VERSION ""

NS_ :

BS_:

BU_: DisplayVCAN

BO_ 3221225472 VECTOR__INDEPENDENT_SIG_MSG: 0 Vector__XXX
 SG_ motpump_min_pwm : 0|7@1+ (1,0) [0|127] "" Vector__XXX
 SG_ override_hvb_min_rpm_Copy_1 : 0|12@1+ (1,0) [0|4095] "RPM" Vector__XXX
 SG_ inv_sig_slope : 0|8@1+ (0.01,0) [0|2.55] "" Vector__XXX
 SG_ ice_fan_override : 0|1@1+ (1,0) [0|1] "" Vector__XXX
 SG_ ip_brk_Ldisp : 0|12@1+ (0.01,0) [0|40.95] "" Vector__XXX
 SG_ ip_brk_Rdisp : 0|12@1+ (0.01,0) [0|40.95] "" Vector__XXX
 SG_ ip_brk_pbrk_LED : 0|1@1+ (1,0) [0|1] "" Vector__XXX
 SG_ ip_brk_sbrk_R_end : 0|1@1+ (1,0) [0|1] "" Vector__XXX
 SG_ ip_brk_sbrk_L_end : 0|1@1+ (1,0) [0|1] "" Vector__XXX
 SG_ ip_brk_Lpres : 0|14@1+ (0.01,0) [0|163.83] "bar" Vector__XXX
 SG_ ip_brk_Rpres : 0|14@1+ (0.01,0) [0|163.83] "bar" Vector__XXX
 SG_ Mushroom_Button : 0|1@1+ (1,0) [0|1] "" Vector__XXX

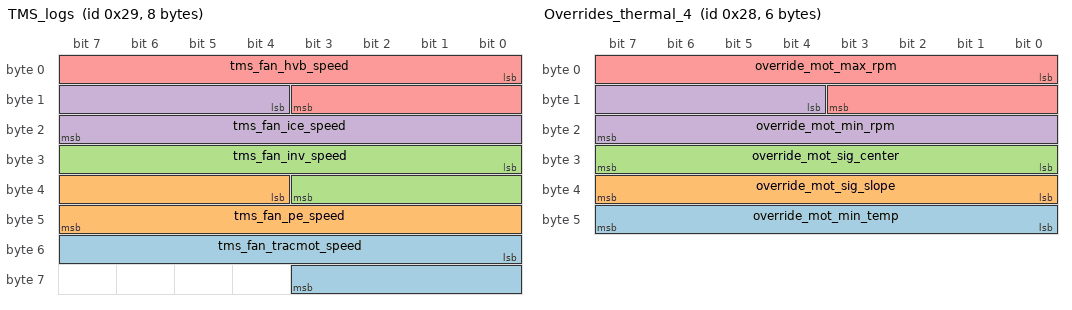
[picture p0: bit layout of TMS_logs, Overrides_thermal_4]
BO_ 41 TMS_logs: 8 Vector__XXX
 SG_ tms_fan_tracmot_speed : 48|12@1+ (1,0) [0|4095] "" Vector__XXX
 SG_ tms_fan_pe_speed : 36|12@1+ (1,0) [0|4095] "" Vector__XXX
 SG_ tms_fan_inv_speed : 24|12@1+ (1,0) [0|4095] "" Vector__XXX
 SG_ tms_fan_ice_speed : 12|12@1+ (1,0) [0|4095] "" Vector__XXX
 SG_ tms_fan_hvb_speed : 0|12@1+ (1,0) [0|4095] "" Vector__XXX

BO_ 40 Overrides_thermal_4: 6 Vector__XXX
 SG_ override_mot_min_temp : 40|8@1+ (1,0) [0|255] "degC" Vector__XXX
 SG_ override_mot_sig_slope : 32|8@1+ (0.01,0) [0|2.55] "" Vector__XXX
 SG_ override_mot_sig_center : 24|8@1+ (1,0) [0|255] "" Vector__XXX
 SG_ override_mot_min_rpm : 12|12@1+ (1,0) [0|4095] "" Vector__XXX
 SG_ override_mot_max_rpm : 0|12@1+ (1,0) [0|4095] "" Vector__XXX

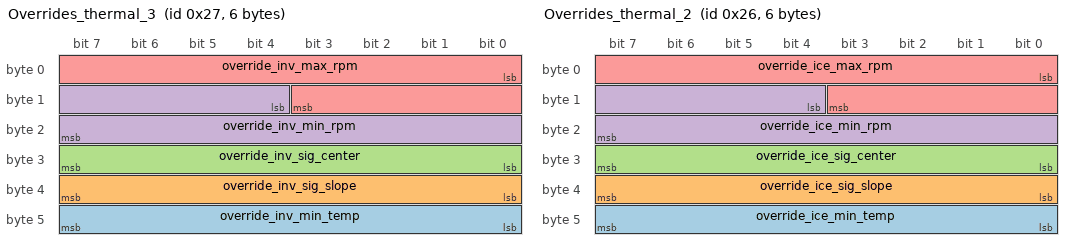
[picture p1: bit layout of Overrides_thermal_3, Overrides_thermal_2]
BO_ 39 Overrides_thermal_3: 6 Vector__XXX
 SG_ override_inv_min_temp : 40|8@1+ (1,0) [0|255] "" Vector__XXX
 SG_ override_inv_sig_slope : 32|8@1+ (0.01,0) [0|2.55] "" Vector__XXX
 SG_ override_inv_sig_center : 24|8@1+ (1,0) [0|255] "" Vector__XXX
 SG_ override_inv_min_rpm : 12|12@1+ (1,0) [0|4095] "" Vector__XXX
 SG_ override_inv_max_rpm : 0|12@1+ (1,0) [0|4095] "" Vector__XXX

BO_ 38 Overrides_thermal_2: 6 Vector__XXX
 SG_ override_ice_min_temp : 40|8@1+ (1,0) [0|255] "" Vector__XXX
 SG_ override_ice_sig_slope : 32|8@1+ (0.01,0) [0|2.55] "" Vector__XXX
 SG_ override_ice_sig_center : 24|8@1+ (1,0) [0|255] "degC" Vector__XXX
 SG_ override_ice_min_rpm : 12|12@1+ (1,0) [0|4095] "RPM" Vector__XXX
 SG_ override_ice_max_rpm : 0|12@1+ (1,0) [0|4095] "RPM" Vector__XXX

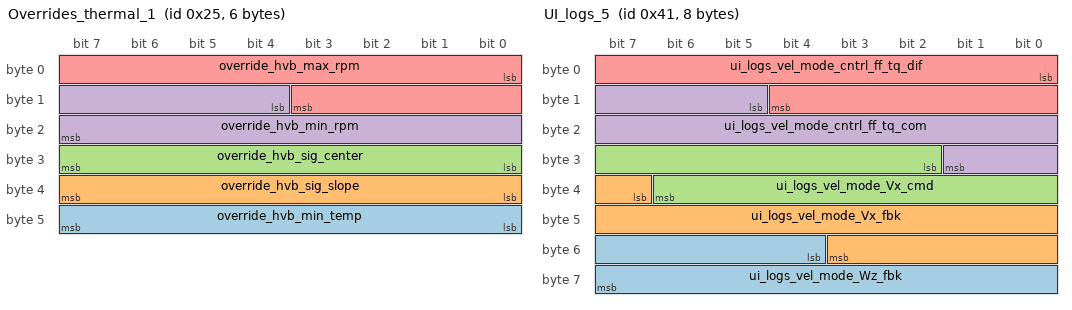
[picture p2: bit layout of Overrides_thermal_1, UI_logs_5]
BO_ 37 Overrides_thermal_1: 6 Vector__XXX
 SG_ override_hvb_min_temp : 40|8@1+ (1,0) [0|255] "" Vector__XXX
 SG_ override_hvb_sig_slope : 32|8@1+ (0.01,0) [0|2.55] "" Vector__XXX
 SG_ override_hvb_sig_center : 24|8@1+ (1,0) [0|255] "degC" Vector__XXX
 SG_ override_hvb_min_rpm : 12|12@1+ (1,0) [0|4095] "RPM" Vector__XXX
 SG_ override_hvb_max_rpm : 0|12@1+ (1,0) [0|4095] "RPM" Vector__XXX

BO_ 65 UI_logs_5: 8 Vector__XXX
 SG_ ui_logs_vel_mode_Wz_fbk : 52|12@1- (0.01,0) [-20.48|20.47] "" Vector__XXX
 SG_ ui_logs_vel_mode_Vx_fbk : 39|13@1- (0.01,0) [-40.96|40.95] "" Vector__XXX
 SG_ ui_logs_vel_mode_Vx_cmd : 26|13@1- (0.01,0) [-40.96|40.95] "" Vector__XXX
 SG_ ui_logs_vel_mode_cntrl_ff_tq_com : 13|13@1- (0.1,0) [-409.6|409.5] "" Vector__XXX
 SG_ ui_logs_vel_mode_cntrl_ff_tq_dif : 0|13@1- (0.1,0) [-409.6|409.5] "" Vector__XXX

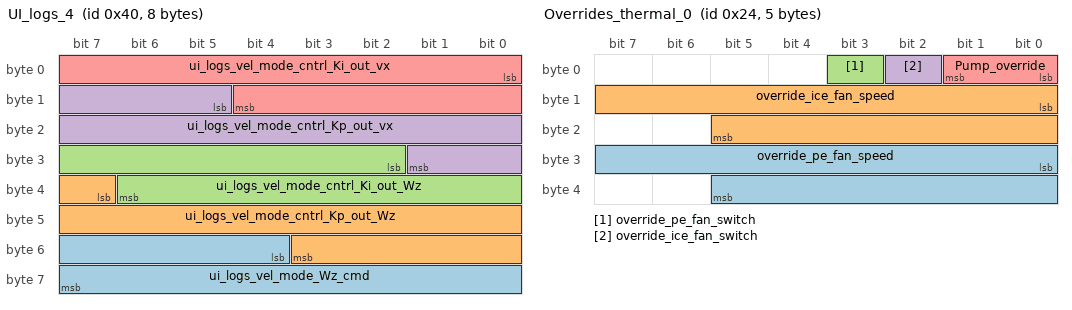
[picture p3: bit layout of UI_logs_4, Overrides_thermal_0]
BO_ 64 UI_logs_4: 8 Vector__XXX
 SG_ ui_logs_vel_mode_Wz_cmd : 52|12@1- (0.01,0) [-20.48|20.47] "" Vector__XXX
 SG_ ui_logs_vel_mode_cntrl_Kp_out_Wz : 39|13@1- (0.1,0) [-409.6|409.5] "" Vector__XXX
 SG_ ui_logs_vel_mode_cntrl_Ki_out_Wz : 26|13@1- (0.1,0) [-4096|4095] "" Vector__XXX
 SG_ ui_logs_vel_mode_cntrl_Kp_out_vx : 13|13@1- (0.1,0) [-409.6|409.5] "" Vector__XXX
 SG_ ui_logs_vel_mode_cntrl_Ki_out_vx : 0|13@1- (0.1,0) [-409.6|409.5] "" Vector__XXX

BO_ 36 Overrides_thermal_0: 5 Vector__XXX
 SG_ override_pe_fan_speed : 24|14@1- (1,0) [-8192|8191] "RPM" Vector__XXX
 SG_ override_ice_fan_speed : 8|14@1- (1,0) [-8192|8191] "RPM" Vector__XXX
 SG_ override_pe_fan_switch : 3|1@1+ (1,0) [0|1] "" Vector__XXX
 SG_ override_ice_fan_switch : 2|1@1+ (1,0) [0|1] "" Vector__XXX
 SG_ Pump_override : 0|2@1+ (1,0) [0|3] "" Vector__XXX

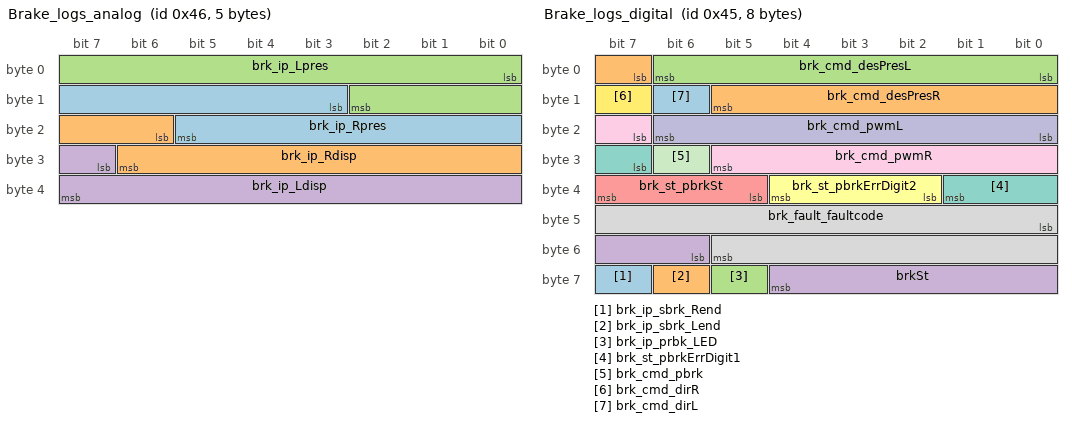
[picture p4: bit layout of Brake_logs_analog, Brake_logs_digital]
BO_ 70 Brake_logs_analog: 5 Vector__XXX
 SG_ brk_ip_Rpres : 11|11@1+ (0.05,0) [0|102.35] "bar" Vector__XXX
 SG_ brk_ip_Rdisp : 22|9@1+ (0.1,0) [0|51.1] "mm" Vector__XXX
 SG_ brk_ip_Lpres : 0|11@1+ (0.05,0) [0|102.35] "bar" Vector__XXX
 SG_ brk_ip_Ldisp : 31|9@1+ (0.1,0) [0|51.1] "mm" Vector__XXX

BO_ 69 Brake_logs_digital: 8 Vector__XXX
 SG_ brk_ip_sbrk_Rend : 63|1@1+ (1,0) [0|1] "" Vector__XXX
 SG_ brk_ip_sbrk_Lend : 62|1@1+ (1,0) [0|1] "" Vector__XXX
 SG_ brk_ip_prbk_LED : 61|1@1+ (1,0) [0|1] "" Vector__XXX
 SG_ brkSt : 54|7@1+ (1,0) [0|127] "" Vector__XXX
 SG_ brk_st_pbrkSt : 37|3@1+ (1,0) [0|7] "" Vector__XXX
 SG_ brk_st_pbrkErrDigit2 : 34|3@1+ (1,0) [0|7] "" Vector__XXX
 SG_ brk_st_pbrkErrDigit1 : 31|3@1+ (1,0) [0|7] "" Vector__XXX
 SG_ brk_fault_faultcode : 40|14@1+ (1,0) [0|16383] "" Vector__XXX
 SG_ brk_cmd_pwmR : 23|7@1+ (1,0) [0|127] "" Vector__XXX
 SG_ brk_cmd_pwmL : 16|7@1+ (1,0) [0|127] "" Vector__XXX
 SG_ brk_cmd_pbrk : 30|1@1+ (1,0) [0|1] "" Vector__XXX
 SG_ brk_cmd_dirR : 15|1@1+ (1,0) [0|1] "" Vector__XXX
 SG_ brk_cmd_dirL : 14|1@1+ (1,0) [0|1] "" Vector__XXX
 SG_ brk_cmd_desPresR : 7|7@1+ (1,0) [0|127] "bar" Vector__XXX
 SG_ brk_cmd_desPresL : 0|7@1+ (1,0) [0|127] "bar" Vector__XXX

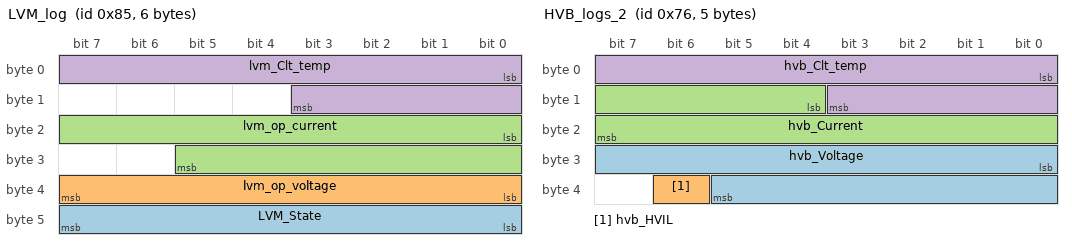
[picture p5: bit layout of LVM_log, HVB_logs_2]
BO_ 133 LVM_log: 6 Vector__XXX
 SG_ LVM_State : 40|8@1+ (1,0) [0|0] "" Vector__XXX
 SG_ lvm_op_voltage : 32|8@1+ (0.1,0) [0|25.5] "" Vector__XXX
 SG_ lvm_op_current : 16|14@1+ (0.1,0) [0|1638.3] "V" Vector__XXX
 SG_ lvm_Clt_temp : 0|12@1- (0.1,0) [-204.8|204.7] "" Vector__XXX

BO_ 118 HVB_logs_2: 5 Vector__XXX
 SG_ hvb_Voltage : 24|14@1+ (0.1,0) [0|1638.3] "V" Vector__XXX
 SG_ hvb_HVIL : 38|1@1+ (1,0) [0|1] "" Vector__XXX
 SG_ hvb_Current : 12|12@1+ (0.1,0) [0|409.5] "A" Vector__XXX
 SG_ hvb_Clt_temp : 0|12@1- (0.1,0) [-204.8|204.7] "degC" Vector__XXX

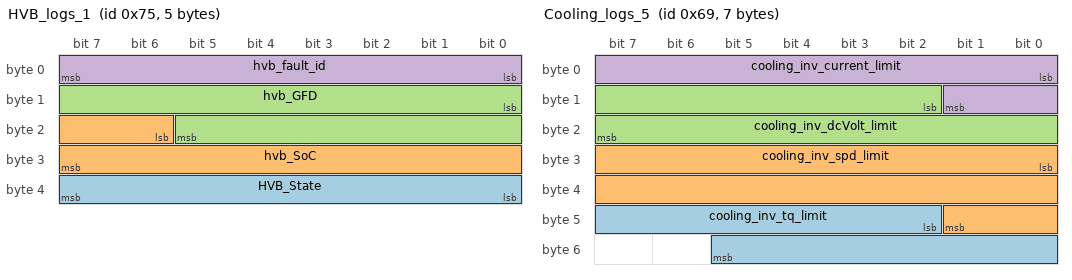
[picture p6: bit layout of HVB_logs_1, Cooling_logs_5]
BO_ 117 HVB_logs_1: 5 Vector__XXX
 SG_ HVB_State : 32|8@1+ (1,0) [0|0] "" Vector__XXX
 SG_ hvb_SoC : 22|10@1+ (0.1,0) [0|102.3] "%" Vector__XXX
 SG_ hvb_GFD : 8|14@1+ (1,0) [0|16383] "mV" Vector__XXX
 SG_ hvb_fault_id : 0|8@1+ (1,0) [0|255] "" Vector__XXX

BO_ 105 Cooling_logs_5: 7 Vector__XXX
 SG_ cooling_inv_tq_limit : 42|12@1- (0.1,0) [-204.8|204.7] "Nm" Vector__XXX
 SG_ cooling_inv_spd_limit : 24|18@1- (0.1,0) [-13107.2|13107.1] "rpm" Vector__XXX
 SG_ cooling_inv_dcVolt_limit : 10|14@1+ (0.1,0) [0|1638.3] "V" Vector__XXX
 SG_ cooling_inv_current_limit : 0|10@1+ (0.1,0) [0|102.3] "A" Vector__XXX

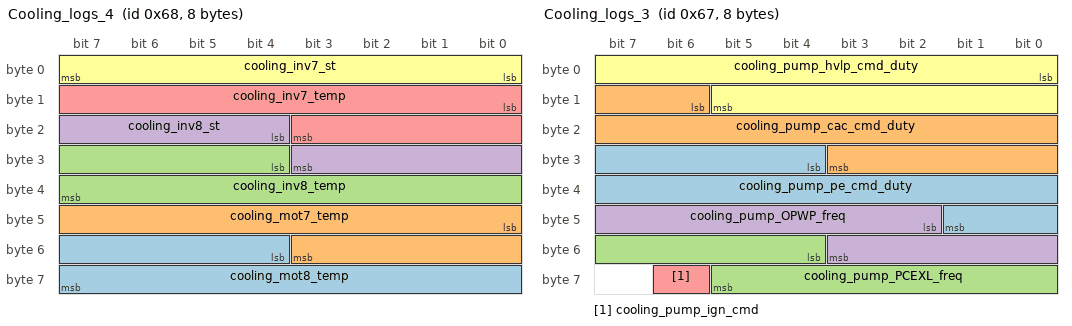
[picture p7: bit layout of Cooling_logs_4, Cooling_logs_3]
BO_ 104 Cooling_logs_4: 8 Vector__XXX
 SG_ cooling_mot8_temp : 52|12@1- (0.1,0) [-204.8|204.7] "degC" Vector__XXX
 SG_ cooling_mot7_temp : 40|12@1- (0.1,0) [-204.8|204.7] "degC" Vector__XXX
 SG_ cooling_inv8_temp : 28|12@1- (0.1,0) [-204.8|204.7] "degC" Vector__XXX
 SG_ cooling_inv8_st : 20|8@1+ (1,0) [0|255] "" Vector__XXX
 SG_ cooling_inv7_temp : 8|12@1- (0.1,0) [-204.8|204.7] "degC" Vector__XXX
 SG_ cooling_inv7_st : 0|8@1+ (1,0) [0|255] "" Vector__XXX

BO_ 103 Cooling_logs_3: 8 Vector__XXX
 SG_ cooling_pump_pe_cmd_duty : 28|14@1+ (-0.01,100) [-63.83|100] "%" Vector__XXX
 SG_ cooling_pump_cac_cmd_duty : 14|14@1+ (-0.01,100) [-63.83|100] "%" Vector__XXX
 SG_ cooling_pump_PCEXL_freq : 52|10@1+ (1,0) [0|1023] "Hz" Vector__XXX
 SG_ cooling_pump_OPWP_freq : 42|10@1+ (1,0) [0|1023] "Hz" Vector__XXX
 SG_ cooling_pump_ign_cmd : 62|1@1+ (1,0) [0|1] "" Vector__XXX
 SG_ cooling_pump_hvlp_cmd_duty : 0|14@1+ (-0.01,100) [-63.83|100] "%" Vector__XXX

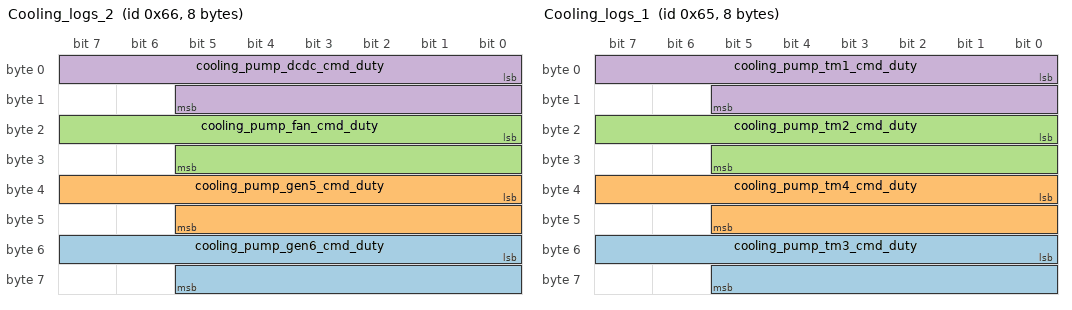
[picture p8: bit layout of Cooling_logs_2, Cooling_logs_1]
BO_ 102 Cooling_logs_2: 8 Vector__XXX
 SG_ cooling_pump_gen6_cmd_duty : 48|14@1+ (-0.01,100) [-63.83|100] "%" Vector__XXX
 SG_ cooling_pump_gen5_cmd_duty : 32|14@1+ (-0.01,100) [-63.83|100] "%" Vector__XXX
 SG_ cooling_pump_fan_cmd_duty : 16|14@1+ (-0.01,100) [-63.83|100] "%" Vector__XXX
 SG_ cooling_pump_dcdc_cmd_duty : 0|14@1+ (-0.01,100) [-63.83|100] "%" Vector__XXX

BO_ 101 Cooling_logs_1: 8 Vector__XXX
 SG_ cooling_pump_tm3_cmd_duty : 48|14@1+ (-0.01,100) [-63.83|100] "%" Vector__XXX
 SG_ cooling_pump_tm4_cmd_duty : 32|14@1+ (-0.01,100) [-63.83|100] "%" Vector__XXX
 SG_ cooling_pump_tm2_cmd_duty : 16|14@1+ (-0.01,100) [-63.83|100] "%" Vector__XXX
 SG_ cooling_pump_tm1_cmd_duty : 0|14@1+ (-0.01,100) [-63.83|100] "%" Vector__XXX

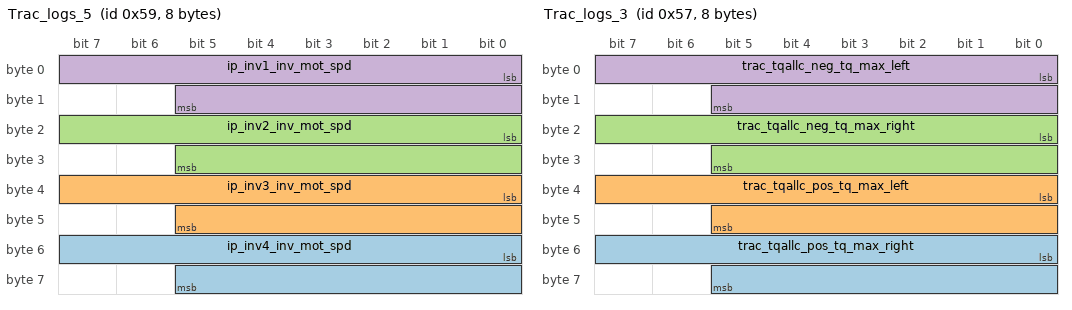
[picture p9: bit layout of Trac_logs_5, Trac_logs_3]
BO_ 89 Trac_logs_5: 8 Vector__XXX
 SG_ ip_inv4_inv_mot_spd : 48|14@1- (1,0) [-8192|8191] "rpm" Vector__XXX
 SG_ ip_inv3_inv_mot_spd : 32|14@1- (1,0) [-8192|8191] "rpm" Vector__XXX
 SG_ ip_inv2_inv_mot_spd : 16|14@1- (1,0) [-8192|8191] "rpm" Vector__XXX
 SG_ ip_inv1_inv_mot_spd : 0|14@1- (1,0) [-8192|8191] "rpm" Vector__XXX

BO_ 88 Trac_logs_4: 4 Vector__XXX
 SG_ trac_der_mot_temp : 16|12@1- (0.1,0) [-204.8|204.7] "degC" Vector__XXX
 SG_ trac_der_inv_temp : 0|12@1- (0.1,0) [-204.8|204.7] "degC" Vector__XXX

BO_ 87 Trac_logs_3: 8 Vector__XXX
 SG_ trac_tqallc_pos_tq_max_right : 48|14@1- (0.1,0) [-819.2|819.1] "Nm" Vector__XXX
 SG_ trac_tqallc_pos_tq_max_left : 32|14@1- (0.1,0) [-819.2|819.1] "Nm" Vector__XXX
 SG_ trac_tqallc_neg_tq_max_right : 16|14@1- (0.1,0) [-819.2|819.1] "Nm" Vector__XXX
 SG_ trac_tqallc_neg_tq_max_left : 0|14@1- (0.1,0) [-819.2|819.1] "Nm" Vector__XXX

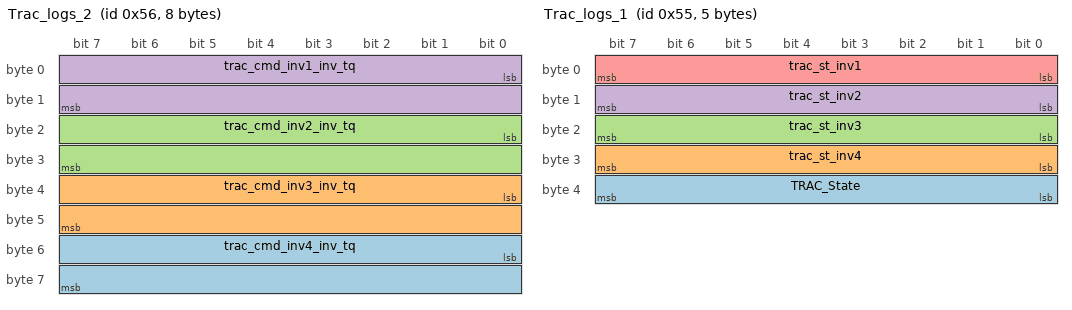
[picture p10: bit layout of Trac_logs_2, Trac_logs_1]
BO_ 86 Trac_logs_2: 8 Vector__XXX
 SG_ trac_cmd_inv4_inv_tq : 48|16@1- (0.01,0) [-327.68|327.67] "Nm" Vector__XXX
 SG_ trac_cmd_inv3_inv_tq : 32|16@1- (0.01,0) [-327.68|327.67] "Nm" Vector__XXX
 SG_ trac_cmd_inv2_inv_tq : 16|16@1- (0.01,0) [-327.68|327.67] "Nm" Vector__XXX
 SG_ trac_cmd_inv1_inv_tq : 0|16@1- (0.01,0) [-327.68|327.67] "Nm" Vector__XXX

BO_ 85 Trac_logs_1: 5 Vector__XXX
 SG_ TRAC_State : 32|8@1+ (1,0) [0|0] "" Vector__XXX
 SG_ trac_st_inv4 : 24|8@1+ (1,0) [0|255] "" Vector__XXX
 SG_ trac_st_inv3 : 16|8@1+ (1,0) [0|255] "" Vector__XXX
 SG_ trac_st_inv2 : 8|8@1+ (1,0) [0|255] "" Vector__XXX
 SG_ trac_st_inv1 : 0|8@1+ (1,0) [0|255] "" Vector__XXX

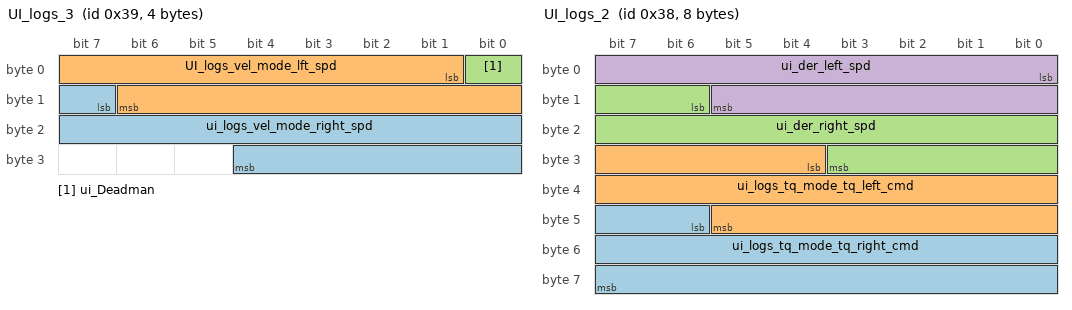
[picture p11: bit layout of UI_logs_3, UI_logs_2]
BO_ 57 UI_logs_3: 4 Vector__XXX
 SG_ ui_logs_vel_mode_right_spd : 15|14@1- (0.01,0) [-81.92|81.91] "m/s" Vector__XXX
 SG_ UI_logs_vel_mode_lft_spd : 1|14@1- (0.01,0) [-81.92|81.91] "m/s" Vector__XXX
 SG_ ui_Deadman : 0|1@1+ (1,0) [0|1] "" Vector__XXX

BO_ 56 UI_logs_2: 8 Vector__XXX
 SG_ ui_logs_tq_mode_tq_right_cmd : 46|18@1- (0.01,0) [-1310.72|1310.71] "Nm" Vector__XXX
 SG_ ui_logs_tq_mode_tq_left_cmd : 28|18@1- (0.01,0) [-1310.72|1310.71] "Nm" Vector__XXX
 SG_ ui_der_right_spd : 14|14@1- (0.01,0) [-81.92|81.91] "m/s" Vector__XXX
 SG_ ui_der_left_spd : 0|14@1- (0.01,0) [-81.92|81.91] "m/s" Vector__XXX

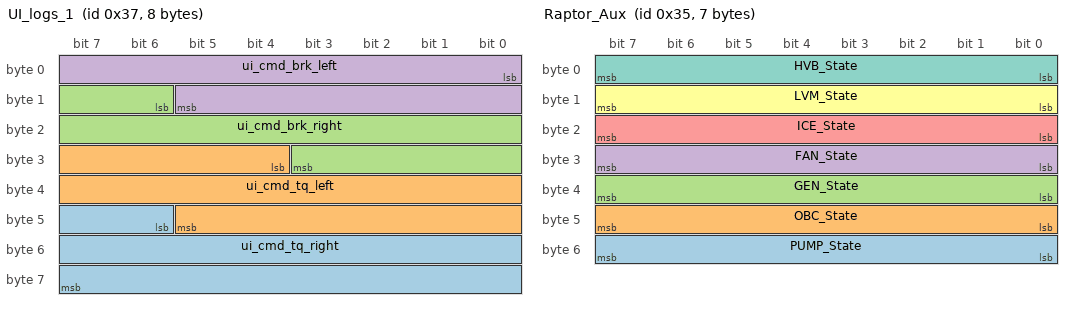
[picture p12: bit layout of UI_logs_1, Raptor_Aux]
BO_ 55 UI_logs_1: 8 Vector__XXX
 SG_ ui_cmd_tq_right : 46|18@1- (0.01,0) [-1310.72|1310.71] "Nm" Vector__XXX
 SG_ ui_cmd_tq_left : 28|18@1- (0.01,0) [-1310.72|1310.71] "Nm" Vector__XXX
 SG_ ui_cmd_brk_right : 14|14@1+ (0.01,0) [0|163.83] "bar" Vector__XXX
 SG_ ui_cmd_brk_left : 0|14@1+ (0.01,0) [0|163.83] "bar" Vector__XXX

BO_ 48 VSS_log: 2 Vector__XXX
 SG_ VSS_stop : 8|1@1+ (1,0) [0|1] "" Vector__XXX
 SG_ VSS_main_batt_V : 0|8@1+ (0.1,0) [0|255] "V" Vector__XXX

BO_ 53 Raptor_Aux: 7 Vector__XXX
 SG_ PUMP_State : 48|8@1+ (1,0) [0|0] "" Vector__XXX
 SG_ OBC_State : 40|8@1+ (1,0) [0|0] "" Vector__XXX
 SG_ GEN_State : 32|8@1+ (1,0) [0|0] "" Vector__XXX
 SG_ FAN_State : 24|8@1+ (1,0) [0|0] "" Vector__XXX
 SG_ ICE_State : 16|8@1+ (1,0) [0|0] "" Vector__XXX
 SG_ LVM_State : 8|8@1+ (1,0) [0|0] "" Vector__XXX
 SG_ HVB_State : 0|8@1+ (1,0) [0|0] "" Vector__XXX

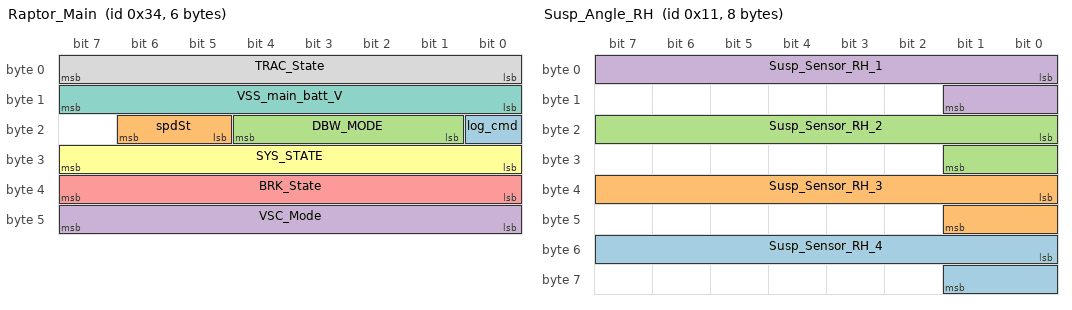
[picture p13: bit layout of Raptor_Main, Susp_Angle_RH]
BO_ 52 Raptor_Main: 6 Vector__XXX
 SG_ log_cmd : 16|1@1+ (1,0) [0|1] "" Vector__XXX
 SG_ spdSt : 21|2@1+ (1,0) [0|3] "" Vector__XXX
 SG_ DBW_MODE : 17|4@1+ (1,0) [0|15] "" Vector__XXX
 SG_ VSC_Mode : 40|8@1+ (1,0) [0|255] "" Vector__XXX
 SG_ BRK_State : 32|8@1+ (1,0) [0|255] "" Vector__XXX
 SG_ SYS_STATE : 24|8@1+ (1,0) [0|0] "" Vector__XXX
 SG_ VSS_main_batt_V : 8|8@1+ (0.1,0) [0|255] "V" Vector__XXX
 SG_ TRAC_State : 0|8@1+ (1,0) [0|0] "" Vector__XXX

BO_ 17 Susp_Angle_RH: 8 Vector__XXX
 SG_ Susp_Sensor_RH_4 : 48|10@1+ (0.1,0) [0|102.3] "" Vector__XXX
 SG_ Susp_Sensor_RH_3 : 32|10@1+ (0.1,0) [0|102.3] "" Vector__XXX
 SG_ Susp_Sensor_RH_2 : 16|10@1+ (0.1,0) [0|102.3] "" Vector__XXX
 SG_ Susp_Sensor_RH_1 : 0|10@1+ (0.1,0) [0|102.3] "" Vector__XXX

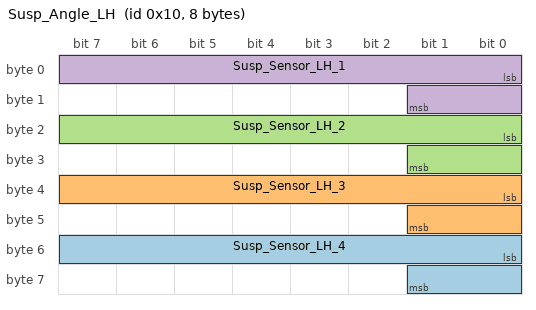
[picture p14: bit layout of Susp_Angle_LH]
BO_ 16 Susp_Angle_LH: 8 Vector__XXX
 SG_ Susp_Sensor_LH_4 : 48|10@1+ (0.1,0) [0|102.3] "" Vector__XXX
 SG_ Susp_Sensor_LH_3 : 32|10@1+ (0.1,0) [0|102.3] "" Vector__XXX
 SG_ Susp_Sensor_LH_2 : 16|10@1+ (0.1,0) [0|102.3] "" Vector__XXX
 SG_ Susp_Sensor_LH_1 : 0|10@1+ (0.1,0) [0|102.3] "" Vector__XXX

BO_ 1224 LF_IRTS_Brake_5: 2 Vector__XXX
 SG_ LF_Sensor_Temp : 7|16@0+ (0.1,-100) [-100|6453.5] "°C" Vector__XXX

BO_ 1229 RF_IRTS_Brake_5: 2 Vector__XXX
 SG_ RF_Sensor_Temp : 7|16@0+ (0.1,-100) [-100|6453.5] "°C" Vector__XXX

CM_ BO_ 3221225472 "This is a message for not used signals, created by Vector CANdb++ DBC OLE DB Provider.";
CM_ SG_ 48 VSS_main_batt_V "Put a gain of 10 at the input battery voltage";
CM_ SG_ 52 VSS_main_batt_V "Put a gain of 10 at the input battery voltage";
BA_DEF_  "BusType" STRING ;
BA_DEF_DEF_  "BusType" "CAN";
